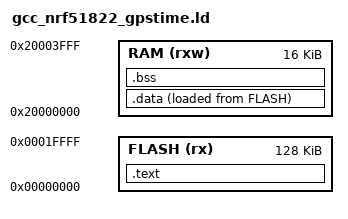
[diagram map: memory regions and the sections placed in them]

MEMORY
{
  FLASH (rx) : ORIGIN = 0x00000000, LENGTH = 128K
  RAM (rxw) : ORIGIN = 0x20000000, LENGTH = 16K
}

ENTRY(Reset_Handler)

SECTIONS
{
    .text :
    {
        __rom_start__ = .;
        KEEP(*(.Vectors))
        *(.text.*)
        *(.text)
        *(.glue_7)
        *(.glue_7t)
        *(.vfp11_veneer)
        *(.v4_bx)
        *(.rodata.*)
        *(.rodata)
        *(.rodata1)
        . = ALIGN(8);
    } >FLASH
    
    __etext = .;
    __data_src_start__ = .;
    
    .data :
    {
        __data_start__ = .;
        *(.ramtext)
        *(.data.*)
        *(.data)
        *(.data1)
        . = ALIGN(8);
        __data_end__ = .;
    } >RAM AT >FLASH
    
    __rom_end__ = __data_src_start__ + SIZEOF(.data);
    
    .bss :
    {
        __bss_start__ = .;
        *(.bss.*)
        *(.bss)
        *(COMMON)
        . = ALIGN(8);
        __bss_end__ = .;
    } >RAM
    
    __stack_top__ = ORIGIN(RAM) + LENGTH(RAM);
    PROVIDE(__stack = __stack_top__);
    
    /* C++ exceptions not supported */
    /DISCARD/ :
    {
        *(.ARM.extab)
        *(.ARM.exidx)
    }
}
